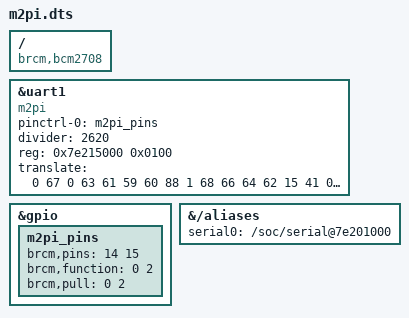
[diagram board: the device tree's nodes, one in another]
/dts-v1/;
/plugin/;

/{
	compatible = "brcm,bcm2708";

	fragment@0 {
		target = <&uart1>;
		__overlay__ {
				compatible = "m2pi";
				pinctrl-names = "default";
				pinctrl-0 = <&m2pi_pins>;
				divider = <2620>;
				status = "okay";
				reg = <0x7e215000 0x0100>;
				translate = /bits/ 8   <0 67 0 63 61 59 60 88 1 68 66 64 62 15 41 0
							0 56 42 0 29 16 2 0 0 0 44 31 30 17 3 0
							0 46 45 32 18 5 4 0 0 57 47 33 20 19 6 0
							0 49 48 35 34 21 7 0 0 100 50 36 22 8 9 0
							0 51 37 23 24 11 10 0 0 52 53 38 39 25 12 0
							0 0 40 0 26 13 0 0 58 54 28 27 0 43 0 0
							0 0 0 0 0 0 14 0 0 79 0 75 71 0 102 0
							82 83 80 76 77 72 1 69 87 78 81 74 55 73 70 0
							0 0 0 65 99 0 0 0 119 0 0 0 0 0 0 0
							0 100 0 0 97 0 0 0 0 0 0 0 0 0 0 0
							0 0 0 0 0 0 0 0 0 0 0 0 0 0 0 0
							0 0 0 0 0 0 0 0 0 0 0 0 0 0 0 0
							0 0 0 0 0 0 0 0 0 0 98 0 0 0 0 0
							0 0 0 0 0 0 0 0 0 0 96 0 0 0 0 0
							0 0 0 0 0 0 0 0 0 107 0 105 102 0 0 0
							110 111 108 0 106 103 0 0 0 0 109 0 210 104 0 0>;
		};
	};

	fragment@1 {
		target = <&gpio>;
		__overlay__ {
			m2pi_pins: m2pi_pins {
				brcm,pins = <14 15>;
				brcm,function = <0 2>; /* input alt5 */
				brcm,pull = <0 2>; /* nopull pulup */
			};
		};
	};

	fragment@2 {
		target-path = "/aliases";
		__overlay__ {
			serial0 = "/soc/serial@7e201000";
		};
	};

};
